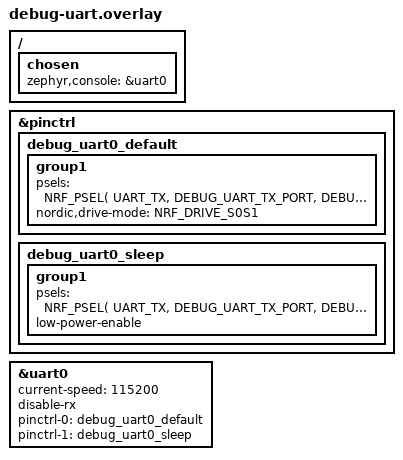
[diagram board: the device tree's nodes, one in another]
#include <zephyr/dt-bindings/pinctrl/nrf-pinctrl.h>

/ {
    chosen {
        zephyr,console = &uart0;
    };
};

&pinctrl {
    debug_uart0_default: debug_uart0_default {
        group1 {
            psels =
                <NRF_PSEL(
                    UART_TX,
                    DEBUG_UART_TX_PORT,
                    DEBUG_UART_TX_PIN
                )>;
            nordic,drive-mode = <NRF_DRIVE_S0S1>;
        };
    };

    debug_uart0_sleep: debug_uart0_sleep {
        group1 {
            psels =
                <NRF_PSEL(
                    UART_TX,
                    DEBUG_UART_TX_PORT,
                    DEBUG_UART_TX_PIN
                )>;
            low-power-enable;
        };
    };
};

&uart0 {
    status = "okay";
    current-speed = <115200>;
    disable-rx;

    pinctrl-0 = <&debug_uart0_default>;
    pinctrl-1 = <&debug_uart0_sleep>;
    pinctrl-names = "default", "sleep";
};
